# nrf5340_application register map
Vendor: Nordic Semiconductor; Series: nrf53; File version: 1
CPU: CM33 r0p4, little endian, MPU, FPU, 3 interrupt priority bits, 69 interrupts
Registers are 32-bit, read-write, reset 0x0 unless marked. A register's access mark holds for its fields unless they carry their own. Offsets are from the block's base; [hi:lo] are bit positions; lines under a group give offsets from that group; {n}, {i} and the like mark numbered series; 'fields as' and 'values as' point back to an identical list.

## CTRLAP_NS — Control access port 0
Base 0x40006000
Same registers: CTRLAP_S 0x50006000
0x400 MAILBOX group — Unspecified
  0x00 RXDATA ro — Data sent from the debugger to the CPU
    [31:0] RXDATA — Data received from debugger
  0x04 RXSTATUS ro — Status to indicate if data sent from the debugger to the CPU has been read
    [0] RXSTATUS — Status of data in register RXDATA
      0=No data pending in register RXDATA; 1=Data pending in register RXDATA
  0x80 TXDATA — Data sent from the CPU to the debugger
    [31:0] TXDATA — Data sent to debugger
  0x84 TXSTATUS ro — Status to indicate if data sent from the CPU to the debugger has been read
    [0] TXSTATUS — Status of data in register TXDATA
      0=No data pending in register TXDATA; 1=Data pending in register TXDATA
0x500 ERASEPROTECT group — Unspecified
  0x00 LOCK rw-once — Lock register ERASEPROTECT.DISABLE from being written until next reset
    [0] LOCK
      0=Unlocked (Register ERASEPROTECT.DISABLE is writeable); 1=Locked (Register ERASEPROTECT.DISABLE is read-only)
  0x04 DISABLE — Disable ERASEPROTECT and perform ERASEALL
    [31:0] KEY — The ERASEALL sequence will be initiated if value of KEY fields are non-zero and KEY fields match on both CPU and debugger side
0x540 APPROTECT group — Unspecified
  0x00 LOCK rw-once — Lock register APPROTECT.DISABLE from being written to until next reset
    [0] LOCK
      0=Unlocked (Register APPROTECT.DISABLE is writeable); 1=Locked (Register APPROTECT.DISABLE is read-only)
  0x04 DISABLE — Disable APPROTECT and enable debug access to non-secure mode
    [31:0] KEY — Disable APPROTECT and enable debug access to non-secure mode until next pin reset if KEY fields match The current APPROTECT value as configured from UICR is bypassed if value of KEY fields are non-zero and KEY fields match on both CPU and debugger side
0x548 SECUREAPPROTECT group — Unspecified
  0x00 LOCK rw-once — Lock register SECUREAPPROTECT.DISABLE from being written until next reset
    [0] LOCK
      0=Unlocked (Register SECUREAPPROTECT.DISABLE is writeable); 1=Locked (Register SECUREAPPROTECT.DISABLE is read-only)
  0x04 DISABLE — Disable SECUREAPPROTECT and enable debug access to secure mode
    [31:0] KEY — Disable SECUREAPPROTECT and enable debug of secure mode until next pin reset if KEY fields match The current SECUREAPPROTECT value as configured from UICR is bypassed if value of KEY fields are non-zero and KEY fields match on both CPU and debugger side
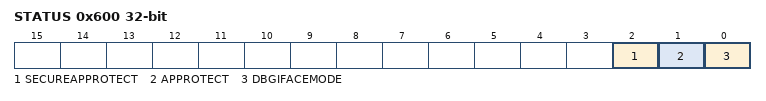
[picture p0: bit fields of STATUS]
0x600 STATUS ro — Status bits for CTRL-AP peripheral
  [2] SECUREAPPROTECT — Status bit for access port protection in secure mode
    0=Disabled (Secure mode access port protection is currently disabled); 1=Enabled (Secure mode access port protection is currently enabled)
  [1] APPROTECT — Status bit for access port protection in non-secure mode
    0=Disabled (Non-secure mode access port protection is currently disabled); 1=Enabled (Non-secure mode access port protection is currently enabled)
  [0] DBGIFACEMODE — Status bit for device debug interface mode
    0=Disabled (No debugger attached); 1=Enabled (Debugger is attached and device is in debug interface mode)

## DPPIC_NS — Distributed programmable peripheral interconnect controller 0
Base 0x40017000
Same registers: DPPIC_S 0x50017000
{0x0+8i} TASKS_CHG[{i}] (i=0..5) group — Channel group tasks
  0x00 EN wo — Description cluster: Enable channel group n
    [0] EN — Enable channel group n
      1=Trigger task
  0x04 DIS wo — Description cluster: Disable channel group n
    [0] DIS — Disable channel group n
      1=Trigger task
{0x80+8i} SUBSCRIBE_CHG[{i}] (i=0..5) group — Subscribe configuration for tasks
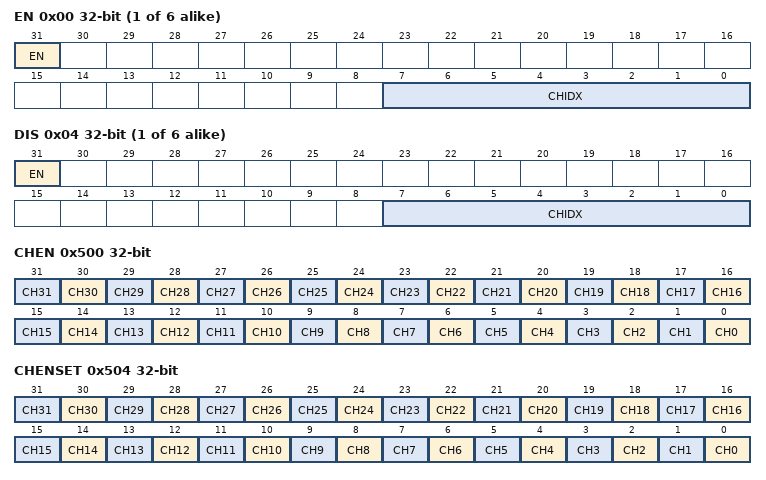
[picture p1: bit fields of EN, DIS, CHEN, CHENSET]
  0x00 EN — Description cluster: Subscribe configuration for task CHG[n].EN
    [31] EN
      0=Disabled (Disable subscription); 1=Enabled (Enable subscription)
    [7:0] CHIDX — DPPI channel that task CHG[n].EN will subscribe to
  0x04 DIS — Description cluster: Subscribe configuration for task CHG[n].DIS
    [31] EN
      values as SUBSCRIBE_CHG[0].EN.EN
    [7:0] CHIDX — DPPI channel that task CHG[n].DIS will subscribe to
0x500 CHEN — Channel enable register
  [all] fields
    0=Disabled (Disable channel); 1=Enabled (Enable channel)
  [n] CH{n} (n=0..31) — Enable or disable channel {n}
0x504 CHENSET write-1-sets — Channel enable set register
  [all] fields
    on read: 0=Disabled (Read: Channel disabled); 1=Enabled (Read: Channel enabled) | on write: 1=Set (Write: Enable channel)
  [n] CH{n} (n=0..31) — Channel {n} enable set register. Writing 0 has no effect.
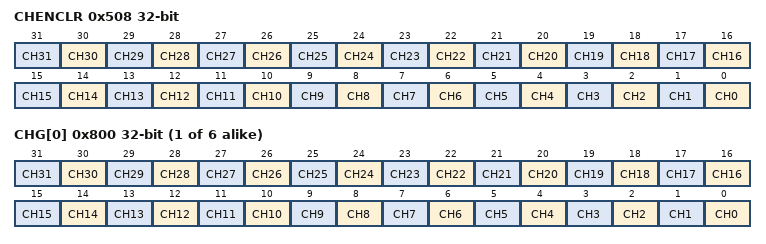
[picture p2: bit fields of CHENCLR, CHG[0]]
0x508 CHENCLR write-1-clears — Channel enable clear register
  [all] fields
    on read: 0=Disabled (Read: Channel disabled); 1=Enabled (Read: Channel enabled) | on write: 1=Clear (Write: Disable channel)
  [n] CH{n} (n=0..31) — Channel {n} enable clear register. Writing 0 has no effect.
{0x800+4i} CHG[{i}] (i=0..5) — Description collection: Channel group n Note: Writes to this register are ignored if either SUBSCRIBE_CHG[n].EN or SUBSCRIBE_CHG[n].DIS is enabled
  [all] fields
    0=Excluded; 1=Included
  [n] CH{n} (n=0..31) — Include or exclude channel {n}
